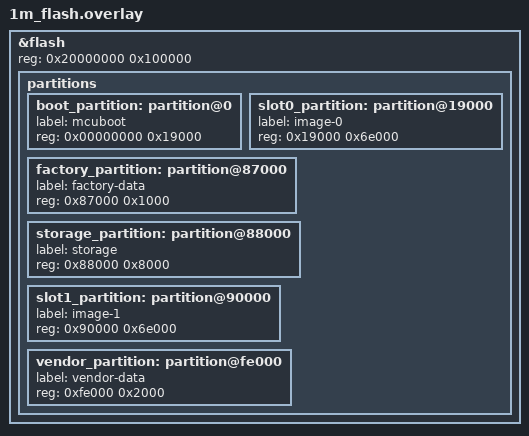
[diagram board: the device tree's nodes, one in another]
&flash {
	reg = <0x20000000 0x100000>;

	partitions {
		/delete-node/ partition@0;
		/delete-node/ partition@20000;
		/delete-node/ partition@88000;
		/delete-node/ partition@f0000;
		/delete-node/ partition@f4000;
		/delete-node/ partition@fe000;
		boot_partition: partition@0 {
			label = "mcuboot";
			reg = <0x00000000 0x19000>;
		};
		slot0_partition: partition@19000 {
			label = "image-0";
			reg = <0x19000 0x6e000>;
		};
		factory_partition: partition@87000 {
			label = "factory-data";
			reg = <0x87000 0x1000>;
		};
		storage_partition: partition@88000 {
			label = "storage";
			reg = <0x88000 0x8000>;
		};
		slot1_partition: partition@90000 {
			label = "image-1";
			reg = <0x90000 0x6e000>;
		};
		vendor_partition: partition@fe000 {
			label = "vendor-data";
			reg = <0xfe000 0x2000>;
		};
	};
};
